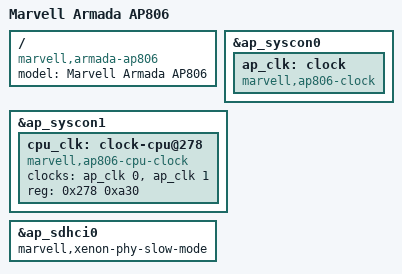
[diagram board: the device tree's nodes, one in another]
// SPDX-License-Identifier: (GPL-2.0+ OR MIT)
/*
 * Copyright (C) 2016 Marvell Technology Group Ltd.
 *
 * Device Tree file for Marvell Armada AP806.
 */

#define AP_NAME		ap806
#include "armada-ap80x.dtsi"

/ {
	model = "Marvell Armada AP806";
	compatible = "marvell,armada-ap806";
};

&ap_syscon0 {
	ap_clk: clock {
		compatible = "marvell,ap806-clock";
		#clock-cells = <1>;
	};
};

&ap_syscon1 {
	cpu_clk: clock-cpu@278 {
		compatible = "marvell,ap806-cpu-clock";
		clocks = <&ap_clk 0>, <&ap_clk 1>;
		#clock-cells = <1>;
		reg = <0x278 0xa30>;
	};
};

&ap_sdhci0 {
	/*
	 * SoC based on AP806 revision A0, A1 and A2 should use slow mode
	 * settings for Ap SDHCI due to HW Erratum HWE-7296210
	 * AP806 revesion B0 and later has this erratum fixed and the slow
	 * mode could be removed in board DTS:
	 *     /delete-property/marvell,xenon-phy-slow-mode;
	 * Starting from B0 revision, the AP SDHCI can run with HS400 timing.
	 */
	marvell,xenon-phy-slow-mode;
};
